# nrf5340_application register map
Vendor: Nordic Semiconductor; Series: nrf53; File version: 1
CPU: CM33 r0p4, little endian, MPU, FPU, 3 interrupt priority bits, 69 interrupts
Registers are 32-bit, read-write, reset 0x0 unless marked. A register's access mark holds for its fields unless they carry their own. Offsets are from the block's base; [hi:lo] are bit positions; lines under a group give offsets from that group; {n}, {i} and the like mark numbered series; 'fields as' and 'values as' point back to an identical list.

## RESET_NS — Reset control 0
Base 0x40005000; alternate view of CLOCK_NS
Same registers: RESET_S 0x50005000 (alternate view of CLOCK_S)
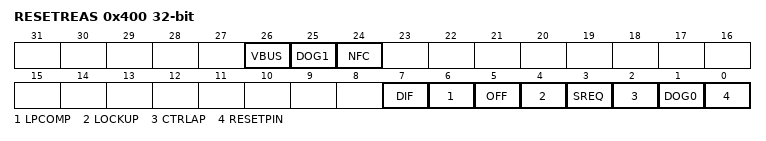
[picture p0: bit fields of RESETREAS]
0x400 RESETREAS — Reset reason
  [all] fields
    0=NotDetected; 1=Detected
  [26] VBUS — Reset after wakeup from System OFF mode due to VBUS rising into valid range
  [25] DOG1 — Reset from application watchdog timer 1 detected
  [24] NFC — Reset after wakeup from System OFF mode due to NFC field being detected
  [7] DIF — Reset due to wakeup from System OFF mode when wakeup is triggered by entering the Debug Interface mode
  [6] LPCOMP — Reset due to wakeup from System OFF mode when wakeup is triggered by ANADETECT signal from LPCOMP
  [5] OFF — Reset due to wakeup from System OFF mode when wakeup is triggered by DETECT signal from GPIO
  [4] LOCKUP — Reset from application CPU lockup detected
  [3] SREQ — Reset from application soft reset detected
  [2] CTRLAP — Reset from application CTRL-AP detected
  [1] DOG0 — Reset from application watchdog timer 0 detected
  [0] RESETPIN — Reset from pin reset detected
0x610 NETWORK group — ULP network core control
  0x04 FORCEOFF reset 0x1 — Force network core off
    [0] FORCEOFF
      0=Release Force-OFF; 1=Hold Force-OFF

## DPPIC_NS — Distributed programmable peripheral interconnect controller 0
Base 0x40017000
Same registers: DPPIC_S 0x50017000
{0x0+8i} TASKS_CHG[{i}] (i=0..5) group — Channel group tasks
  0x00 EN wo — Description cluster: Enable channel group n
    [0] EN — Enable channel group n
      1=Trigger task
  0x04 DIS wo — Description cluster: Disable channel group n
    [0] DIS — Disable channel group n
      1=Trigger task
{0x80+8i} SUBSCRIBE_CHG[{i}] (i=0..5) group — Subscribe configuration for tasks
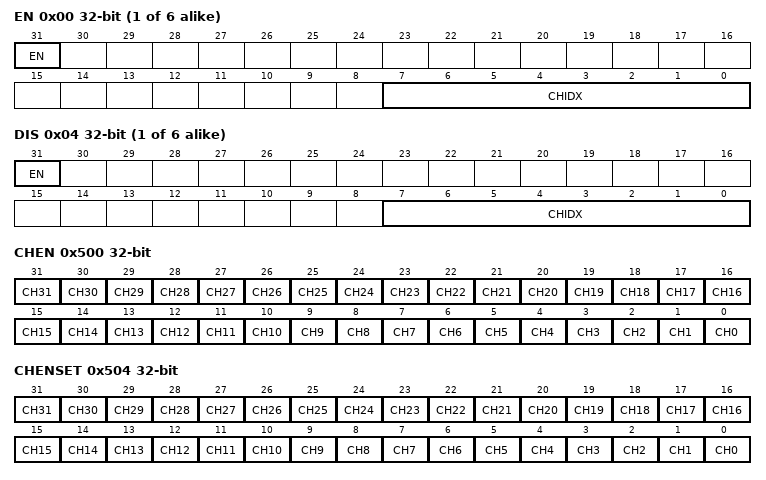
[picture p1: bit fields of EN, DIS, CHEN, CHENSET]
  0x00 EN — Description cluster: Subscribe configuration for task CHG[n].EN
    [31] EN
      0=Disabled (Disable subscription); 1=Enabled (Enable subscription)
    [7:0] CHIDX — DPPI channel that task CHG[n].EN will subscribe to
  0x04 DIS — Description cluster: Subscribe configuration for task CHG[n].DIS
    [31] EN
      values as SUBSCRIBE_CHG[0].EN.EN
    [7:0] CHIDX — DPPI channel that task CHG[n].DIS will subscribe to
0x500 CHEN — Channel enable register
  [all] fields
    0=Disabled (Disable channel); 1=Enabled (Enable channel)
  [n] CH{n} (n=0..31) — Enable or disable channel {n}
0x504 CHENSET write-1-sets — Channel enable set register
  [all] fields
    on read: 0=Disabled (Read: Channel disabled); 1=Enabled (Read: Channel enabled) | on write: 1=Set (Write: Enable channel)
  [n] CH{n} (n=0..31) — Channel {n} enable set register. Writing 0 has no effect.
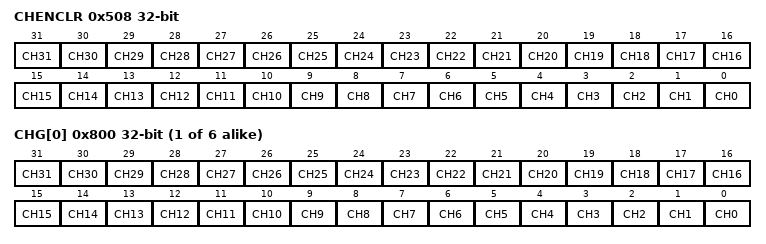
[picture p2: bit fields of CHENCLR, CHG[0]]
0x508 CHENCLR write-1-clears — Channel enable clear register
  [all] fields
    on read: 0=Disabled (Read: Channel disabled); 1=Enabled (Read: Channel enabled) | on write: 1=Clear (Write: Disable channel)
  [n] CH{n} (n=0..31) — Channel {n} enable clear register. Writing 0 has no effect.
{0x800+4i} CHG[{i}] (i=0..5) — Description collection: Channel group n Note: Writes to this register are ignored if either SUBSCRIBE_CHG[n].EN or SUBSCRIBE_CHG[n].DIS is enabled
  [all] fields
    0=Excluded; 1=Included
  [n] CH{n} (n=0..31) — Include or exclude channel {n}

## WDT0_NS — Watchdog Timer 0
Base 0x40018000
Same registers: WDT1_NS 0x40019000, WDT0_S 0x50018000, WDT1_S 0x50019000
0x00 TASKS_START wo — Start WDT
  [0] TASKS_START
    1=Trigger task
0x04 TASKS_STOP wo — Stop WDT
  [0] TASKS_STOP
    1=Trigger task
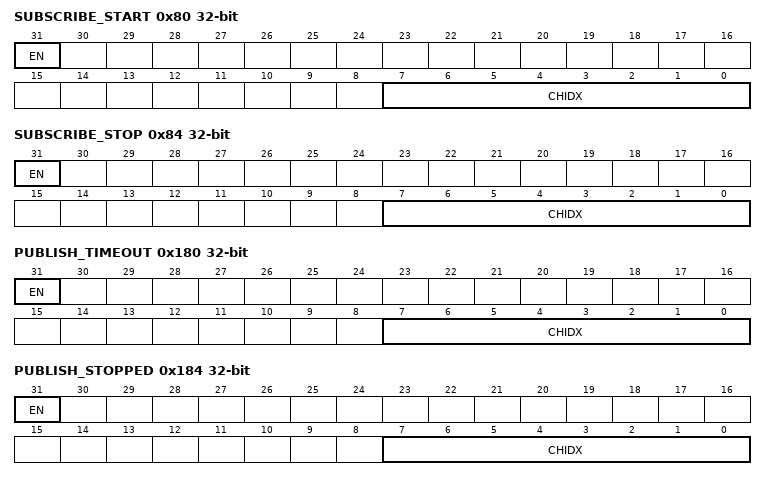
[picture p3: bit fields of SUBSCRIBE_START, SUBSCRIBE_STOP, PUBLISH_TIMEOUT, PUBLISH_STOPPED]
0x80 SUBSCRIBE_START — Subscribe configuration for task START
  [31] EN
    0=Disabled (Disable subscription); 1=Enabled (Enable subscription)
  [7:0] CHIDX — DPPI channel that task START will subscribe to
0x84 SUBSCRIBE_STOP — Subscribe configuration for task STOP
  [31] EN
    values as SUBSCRIBE_START.EN
  [7:0] CHIDX — DPPI channel that task STOP will subscribe to
0x100 EVENTS_TIMEOUT — Watchdog timeout
  [0] EVENTS_TIMEOUT
    0=NotGenerated (Event not generated); 1=Generated (Event generated)
0x104 EVENTS_STOPPED — Watchdog stopped
  [0] EVENTS_STOPPED
    values as EVENTS_TIMEOUT.EVENTS_TIMEOUT
0x180 PUBLISH_TIMEOUT — Publish configuration for event TIMEOUT
  [31] EN
    0=Disabled (Disable publishing); 1=Enabled (Enable publishing)
  [7:0] CHIDX — DPPI channel that event TIMEOUT will publish to.
0x184 PUBLISH_STOPPED — Publish configuration for event STOPPED
  [31] EN
    values as PUBLISH_TIMEOUT.EN
  [7:0] CHIDX — DPPI channel that event STOPPED will publish to.
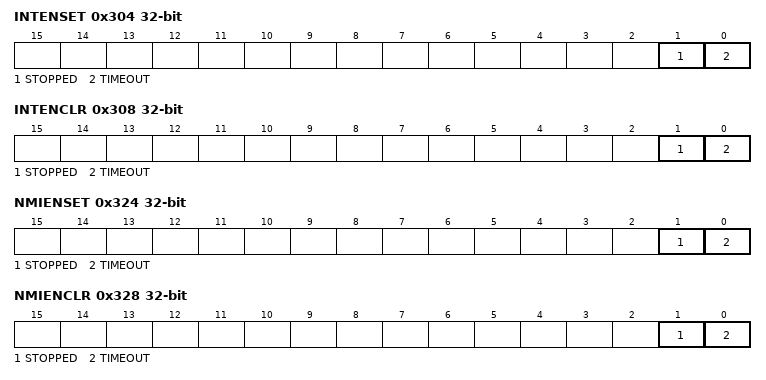
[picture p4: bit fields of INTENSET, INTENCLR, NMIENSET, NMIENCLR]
0x304 INTENSET — Enable interrupt
  [1] STOPPED — Write '1' to enable interrupt for event STOPPED
    on read: 0=Disabled (Read: Disabled); 1=Enabled (Read: Enabled) | on write: 1=Set (Enable)
  [0] TIMEOUT — Write '1' to enable interrupt for event TIMEOUT
    values as STOPPED
0x308 INTENCLR — Disable interrupt
  [1] STOPPED — Write '1' to disable interrupt for event STOPPED
    on read: 0=Disabled (Read: Disabled); 1=Enabled (Read: Enabled) | on write: 1=Clear (Disable)
  [0] TIMEOUT — Write '1' to disable interrupt for event TIMEOUT
    values as STOPPED
0x324 NMIENSET — Enable interrupt
  fields as INTENSET
0x328 NMIENCLR — Disable interrupt
  fields as INTENCLR
0x400 RUNSTATUS ro
  [0] RUNSTATUSWDT — Indicates whether or not WDT is running
    0=NotRunning (Watchdog is not running); 1=Running (Watchdog is running)
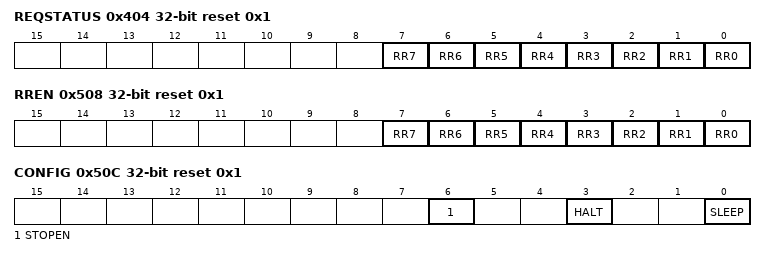
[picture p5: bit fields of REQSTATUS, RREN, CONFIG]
0x404 REQSTATUS ro reset 0x1 — Request status
  [n] RR{n} (n=0..7) — Request status for RR[{n}] register
    0=DisabledOrRequested (RR[{n}] register is not enabled, or are already requesting reload); 1=EnabledAndUnrequested (RR[{n}] register is enabled, and are not yet requesting reload)
0x504 CRV reset 0xFFFFFFFF — Counter reload value
  [31:0] CRV — Counter reload value in number of cycles of the 32.768 kHz clock
0x508 RREN reset 0x1 — Enable register for reload request registers
  [n] RR{n} (n=0..7) — Enable or disable RR[{n}] register
    0=Disabled (Disable RR[{n}] register); 1=Enabled (Enable RR[{n}] register)
0x50C CONFIG reset 0x1 — Configuration register
  [6] STOPEN — Allow stopping WDT
    0=Disable (Do not allow stopping WDT); 1=Enable (Allow stopping WDT)
  [3] HALT — Configure WDT to either be paused, or kept running, while the CPU is halted by the debugger
    0=Pause WDT while the CPU is halted by the debugger; 1=Run (Keep WDT running while the CPU is halted by the debugger)
  [0] SLEEP — Configure WDT to either be paused, or kept running, while the CPU is sleeping
    0=Pause WDT while the CPU is sleeping; 1=Run (Keep WDT running while the CPU is sleeping)
0x520 TSEN wo — Task stop enable
  [31:0] TSEN — Allow stopping WDT
    0x6E524635=Enable (Value to allow stopping WDT)
{0x600+4i} RR[{i}] (i=0..7) wo — Description collection: Reload request n
  [31:0] RR — Reload request register
    0x6E524635=Reload (Value to request a reload of the watchdog timer)
